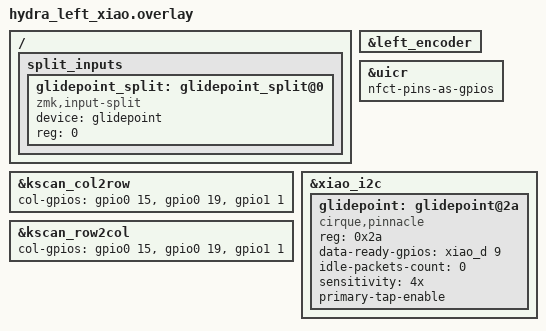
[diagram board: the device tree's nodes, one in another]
#include "hydra_xiao.dtsi"

/* ── COL1-3: XIAO Plus D11-D13 (P0.15/P0.19/P1.01) ── */
&kscan_col2row {
    col-gpios
        = <&gpio0 15 GPIO_ACTIVE_HIGH>  // COL1 D11/P0.15
        , <&gpio0 19 GPIO_ACTIVE_HIGH>  // COL2 D12/P0.19
        , <&gpio1  1 GPIO_ACTIVE_HIGH>  // COL3 D13/P1.01
        ;
};

&kscan_row2col {
    col-gpios
        = <&gpio0 15 (GPIO_ACTIVE_HIGH | GPIO_PULL_DOWN)>  // COL1 D11/P0.15
        , <&gpio0 19 (GPIO_ACTIVE_HIGH | GPIO_PULL_DOWN)>  // COL2 D12/P0.19
        , <&gpio1  1 (GPIO_ACTIVE_HIGH | GPIO_PULL_DOWN)>  // COL3 D13/P1.01
        ;
};

&left_encoder { status = "okay"; };

/* ── Unlock NFC pins P0.09/P0.10 for OLED CS/DC GPIO ── */
&uicr {
    nfct-pins-as-gpios;
};

/* ── I2C Cirque trackpad: board xiao_i2c already has pinctrl for D4/D5 ── */
&xiao_i2c {
    status = "okay";
    glidepoint: glidepoint@2a {
        compatible = "cirque,pinnacle";
        status = "okay";
        reg = <0x2a>;
        data-ready-gpios = <&xiao_d 9 (GPIO_ACTIVE_HIGH)>;  // D9/P1.14 DR
        idle-packets-count = <0>;
        sensitivity = "4x";
        primary-tap-enable;
    };
};

/ {
    split_inputs {
        #address-cells = <1>;
        #size-cells = <0>;

        glidepoint_split: glidepoint_split@0 {
            compatible = "zmk,input-split";
            device = <&glidepoint>;
            reg = <0>;
        };
    };
};
